# LIS331EB register map
Vendor: STMicroelectronics; Series: LIS331EB; File version: 1.0
CPU: CM0 r0p0, little endian, no MPU, no FPU, 5 interrupt priority bits
Registers are 32-bit, read-write, reset 0x0 unless marked. A register's access mark holds for its fields unless they carry their own. Offsets are from the block's base; [hi:lo] are bit positions; {n}, {i} and the like mark numbered series; 'fields as' and 'values as' point back to an identical list.

## DUALTIMER0
Base 0xA6400000
Same registers: DUALTIMER4 0xA6800000, DUALTIMER1 0xA7400000, DUALTIMER5 0xA7800000, DUALTIMER2 0xA8400000, DUALTIMER6 0xA8800000, DUALTIMER3 0xA9400000, DUALTIMER7 0xA9800000
0x00 Timer1Load — Load register
0x04 Timer1Value ro reset 0xFFFFFFFF — Current value register
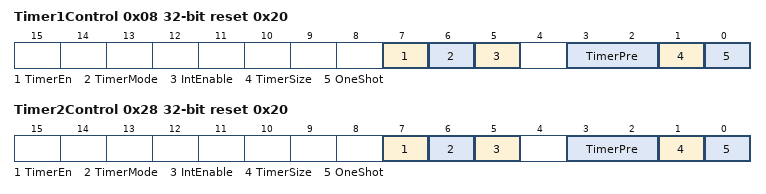
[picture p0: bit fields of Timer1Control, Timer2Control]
0x08 Timer1Control reset 0x20 — Control register
  [7] TimerEn — Enable bit
  [6] TimerMode — Mode bit
    0=FreeRunning (Timer module is in free-running mode); 1=Periodic (Timer module is in periodic mode)
  [5] IntEnable — Interrupt Enable bit
  [3:2] TimerPre — Prescale bits
    0=0 stages of prescale, clock is divided by 1; 1=4 stages of prescale, clock is divided by 16; 2=8 stages of prescale, clock is divided by 256
  [1] TimerSize — Selects 16/32 bit counter operation
    0=16BitCounter; 1=32BitCounter
  [0] OneShot — Selects one-shot or wrapping counter mode
    0=WrappingMode; 1=OneShot
0x0C Timer1IntClr wo — Interrupt clear register
0x10 Timer1RIS ro (reset mask 0x1) — Raw interrupt status register
0x14 Timer1MIS ro (reset mask 0x1) — Masked interrupt status register
0x18 Timer1BGLoad — Background load register
0x20 Timer2Load — Load register
0x24 Timer2Value ro reset 0xFFFFFFFF — Current value register
0x28 Timer2Control reset 0x20 — Control register
  fields as Timer1Control
0x2C Timer2IntClr wo — Interrupt clear register
0x30 Timer2RIS ro (reset mask 0x1) — Raw interrupt status register
0x34 Timer2MIS ro (reset mask 0x1) — Masked interrupt status register
0x38 Timer2BGLoad — Background load register
0xF00 TimerITCR (reset mask 0x1) — Integration test control register
0xF04 TimerITOP wo (reset mask 0x3) — Integration test output set register
0xFE0 TimerPeriphID0 ro reset 0x4 (reset mask 0xFF) — Timer peripheral ID0 register
0xFE4 TimerPeriphID1 ro reset 0x18 (reset mask 0xFF) — Timer peripheral ID1 register
0xFE8 TimerPeriphID2 ro reset 0x14 (reset mask 0xFF) — Timer peripheral ID2 register
0xFEC TimerPeriphID3 ro (reset mask 0xFF) — Timer peripheral ID3 register
0xFF0 TimerPCellID0 ro reset 0xD (reset mask 0xFF) — PrimeCell ID0 register
0xFF4 TimerPCellID1 ro reset 0xF0 (reset mask 0xFF) — PrimeCell ID1 register
0xFF8 TimerPCellID2 ro reset 0x5 (reset mask 0xFF) — PrimeCell ID2 register
0xFFC TimerPCellID3 ro reset 0xB1 (reset mask 0xFF) — PrimeCell ID3 register

## WATCHDOG
Base 0xAA000000
0x00 WDT_LR reset 0xFFFFFFFF — Watchdog Load Register
  [31:0] WDT_LOAD range 1..0xFFFFFFFF — Watchdog Load Value
0x04 WDT_VAL ro reset 0xFFFFFFFF — Watchdog Value Register
  [31:0] WDTVAL — Watchdog Load Value
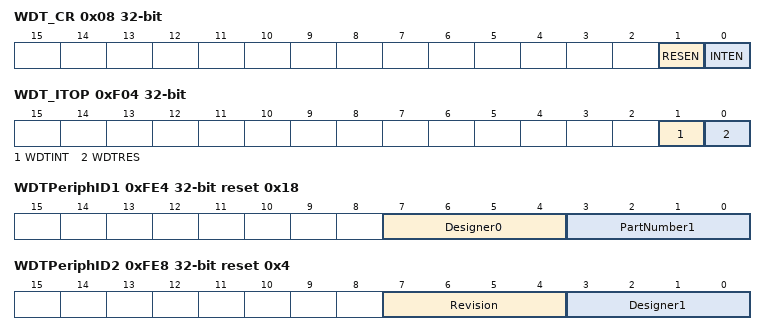
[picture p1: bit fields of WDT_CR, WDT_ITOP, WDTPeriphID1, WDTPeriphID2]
0x08 WDT_CR — Watchdog Control Register
  [1] RESEN — Watchdog Reset Enable
  [0] INTEN — Watchdog Interrupt Enable
0x0C WDT_ICR write-clears — Watchdog Interrupt Clear Register
  [31:0] WDTICLR — Watchdog Interrupt Enable
0x10 WDT_RIS ro — Watchdog Raw Interrupt Status Register
  [0] WDTRIS — Watchdog Raw Interrupt Status
0x14 WDT_MIS ro — Watchdog Masked Interrupt Status Register
  [0] WDTMIS — Watchdog Masked Interrupt Status
0xC00 WDT_LOCK — Watchdog Lock Register
  [31:0] LOCKVAL — Watchdog Lock value
0xF00 WDT_ITCR — WDT Integration Test Control Register
  [0] ITME — Integration Test Mode Enable bit
0xF04 WDT_ITOP — WDT Integration Test Output Set Register
  [1] WDTINT — Integration Test WDTINT Output level
  [0] WDTRES — Integration Test WDTRES Output level
0xFE0 WDTPeriphID0 ro reset 0x5 — Watchdog Peripheral Identification Register 0
  [7:0] PartNumber0 — These bits read back as 0x05
0xFE4 WDTPeriphID1 ro reset 0x18 — Watchdog Peripheral Identification Register 1
  [7:4] Designer0 — These bits read back as 0x01
  [3:0] PartNumber1 — These bits read back as 0x08
0xFE8 WDTPeriphID2 ro reset 0x4 — Watchdog Peripheral Identification Register 2
  [7:4] Revision — These bits read back as 0x00
  [3:0] Designer1 — These bits read back as 0x04
0xFEC WDTPeriphID3 ro — Watchdog Peripheral Identification Register 3
  [7:0] Configuration — These bits read back as 0x00
0xFF0 WDTPCellID0 ro reset 0xD — Watchdog PCell Identification Register 0
  [7:0] WDTPCellID0 — These bits read back as 0x0D
0xFF4 WDTPCellID1 ro reset 0xF0 — Watchdog PCell Identification Register 1
  [7:0] WDTPCellID1 — These bits read back as 0xF0
0xFF8 WDTPCellID2 ro reset 0x5 — Watchdog PCell Identification Register 2
  [7:0] WDTPCellID2 — These bits read back as 0x05
0xFFC WDTPCellID3 ro reset 0xB1 — Watchdog PCell Identification Register 3
  [7:0] WDTPCellID3 — These bits read back as 0xB1

## CRMU — Clock and Reset Management Unit
Base 0xAB000000
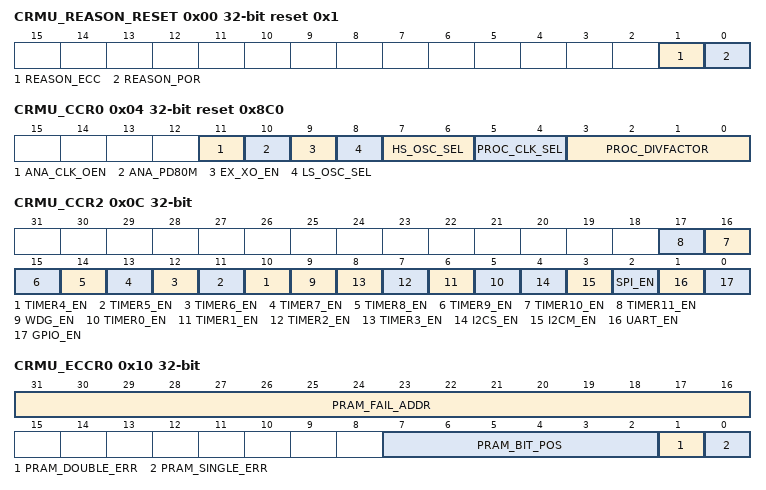
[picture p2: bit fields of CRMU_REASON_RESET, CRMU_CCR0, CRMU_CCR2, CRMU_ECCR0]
0x00 CRMU_REASON_RESET ro reset 0x1 — Reset reason
  [1] REASON_ECC — Reset caused by ECC
  [0] REASON_POR — Reset caused by POR
0x04 CRMU_CCR0 reset 0x8C0 — Clock control register 0
  [11] ANA_CLK_OEN — Output enable for DIO6 in serial0 and serial1 modes
  [10] ANA_PD80M — Enable for 80MHz internal oscillator
  [9] EX_XO_EN — Enable for external oscillator
  [8] LS_OSC_SEL — Select internal 32KHz clock oscillator as source for 32KHz clock
  [7:6] HS_OSC_SEL — Select the clock output from the 3-way clock-switch. It is the root point for the processor clock
    0=80MHz clock; 1=32KHz clock; 2=Ext (External oscillator clock); 3=Ext2 (External oscillator clock)
  [5:4] PROC_CLK_SEL — Select for processor clock switch
    0=ClkDiv5 (Clock divided by 5); 1=ClkDivProcDiv (32KHz/80MHz/EXT_XO clock divided by Proc Divfactor); 2=ClkDiv3 (32KHz/80MHz/EXT_XO clock divided by 3); 3=Clk (32KHz/80MHz/EXT_XO clock)
  [3:0] PROC_DIVFACTOR — Divide factor for the even clock divider
    1=ClkDiv2 (Clock divided by 2); 2=ClkDiv4 (Clock divided by 4); 3=ClkDiv6 (Clock divided by 6); 4=ClkDiv8 (Clock divided by 8); 5=ClkDiv10 (Clock divided by 10); 6=ClkDiv16 (Clock divided by 16); 7=ClkDiv20 (Clock divided by 20); 8=ClkDiv32 (Clock divided by 32)
0x08 CRMU_CCR1 — Clock control register 1
  [6:0] UART_DIVFACTOR — Uart clock divide factor
0x0C CRMU_CCR2 — Clock control register 2
  [n+6] TIMER{n}_EN (n=4..11) — Enable for TIMER{n}
  [9] WDG_EN — Enable for WDG
  [n+5] TIMER{n}_EN (n=0..3) — Enable for TIMER{n}
  [4] I2CS_EN — Enable for I2CS
  [3] I2CM_EN — Enable for I2CM
  [2] SPI_EN — Enable for SPI
  [1] UART_EN — Enable for UART
  [0] GPIO_EN — Enable for GPIO
0x10 CRMU_ECCR0 ro — Error correction code register 0
  [31:16] PRAM_FAIL_ADDR — ECC fail address
  [7:2] PRAM_BIT_POS — ECC fail bit position provided after single error correction
  [1] PRAM_DOUBLE_ERR — ECC double error detection signal
  [0] PRAM_SINGLE_ERR — ECC single error correction signal
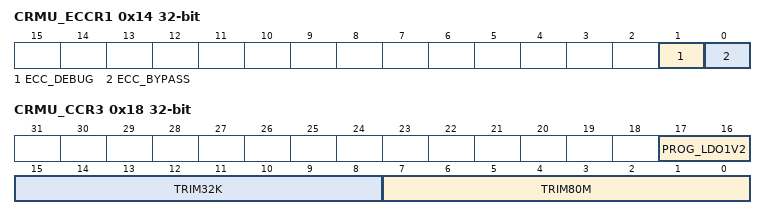
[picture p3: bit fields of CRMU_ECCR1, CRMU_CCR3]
0x14 CRMU_ECCR1 — Error correction code register 1
  [1] ECC_DEBUG — Put the ECC in debug mode used for test only
  [0] ECC_BYPASS — Bypass the ECC
0x18 CRMU_CCR3 — Clock control register 3
  [17:16] PROG_LDO1V2 — Program LDO_DIG1V2
  [15:8] TRIM32K — Trimming for 32KHz clock
  [7:0] TRIM80M — Trimming for 80MHz clock
